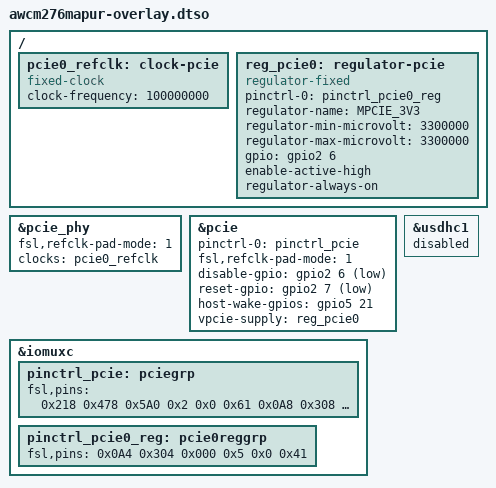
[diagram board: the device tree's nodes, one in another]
// SPDX-License-Identifier: (GPL-2.0+ OR MIT)
/*
 * Copyright 2023 ADLINK Technology Corp.
 *
 * Author: Po Cheng <po.cheng@adlinktech.com>
 */

/dts-v1/;
/plugin/;

/ {
	fragment@0 {
		target-path = "/";
		__overlay__ {
			pcie0_refclk: clock-pcie {
				compatible = "fixed-clock";
				#clock-cells = <0>;
				clock-frequency = <100000000>;
			};

			reg_pcie0: regulator-pcie {
				compatible = "regulator-fixed";
				pinctrl-names = "default";
				pinctrl-0 = <&pinctrl_pcie0_reg>;
				regulator-name = "MPCIE_3V3";
				regulator-min-microvolt = <3300000>;
				regulator-max-microvolt = <3300000>;
				gpio = <&gpio2 6 0>; /* GPIO_ACTIVE_HIGH = 0 */
				enable-active-high;
				regulator-always-on;
			};
		};
	};

	fragment@1 {
		target = <&pcie_phy>;
		__overlay__ {
			fsl,refclk-pad-mode = <1>; /* IMX8_PCIE_REFCLK_PAD_INPUT = 1 */
			clocks = <&pcie0_refclk>;
			clock-names = "ref";
			status = "okay";
		};
	};

	fragment@2 {
		target = <&pcie>;
		__overlay__ {
			pinctrl-names = "default";
			pinctrl-0 = <&pinctrl_pcie>;
			fsl,refclk-pad-mode = <1>;
			disable-gpio = <&gpio2 6 1>;  /* GPIO_ACTIVE_LOW = 1 */
			reset-gpio = <&gpio2 7 1>;  /* GPIO_ACTIVE_LOW = 1 */
			host-wake-gpios = <&gpio5 21 8>; /* IRQ_TYPE_LEVEL_LOW = 8 */
			vpcie-supply = <&reg_pcie0>;
			status = "okay";
		};
	};

	fragment@3 {
		target = <&iomuxc>;
		__overlay__ {
			pinctrl_pcie: pciegrp {
				fsl,pins = <
					/* MX8MP_IOMUXC_I2C4_SCL__PCIE_CLKREQ_B - open drain, pull up */
					0x218 0x478 0x5A0 0x2 0x0	0x61
					/* MX8MP_IOMUXC_SD1_DATA5__GPIO2_IO07 - PCIe Reset */
					0x0A8 0x308 0x000 0x5 0x0	0x41
					/* MX8MP_IOMUXC_I2C4_SDA__GPIO5_IO21 - PCIe Wakeup */
					0x21C 0x47C 0x000 0x5 0x0	0x1c4
				>;
			};

			pinctrl_pcie0_reg: pcie0reggrp {
				fsl,pins = <
					/* MX8MP_IOMUXC_SD1_DATA4__GPIO2_IO06 - PCIe disable */
					0x0A4 0x304 0x000 0x5 0x0	0x41		>;
			};
		};
	};

	fragment@4 {
		target = <&usdhc1>;
		__overlay__ {
			status = "disabled";
		};
	};
};

